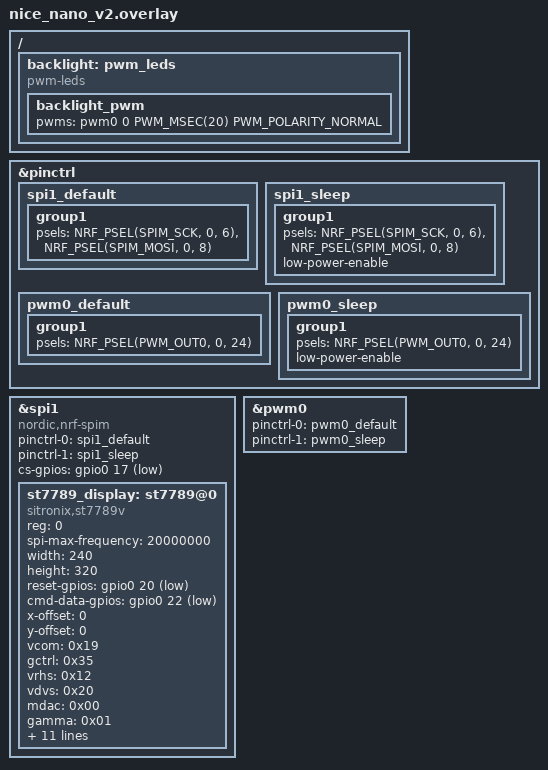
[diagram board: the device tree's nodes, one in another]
// Device tree overlay for ST7789 TFT display connected via SPI
// Add this to your board's .overlay file or include in your keymap


&pinctrl {
    spi1_default: spi1_default {
        group1 {
            psels = <NRF_PSEL(SPIM_SCK, 0, 6)>,   // SCK - Pin 0.06 (D4)
                    <NRF_PSEL(SPIM_MOSI, 0, 8)>;  // MOSI - Pin 0.08 (D6)
        };
    };

    spi1_sleep: spi1_sleep {
        group1 {
            psels = <NRF_PSEL(SPIM_SCK, 0, 6)>,
                    <NRF_PSEL(SPIM_MOSI, 0, 8)>;
            low-power-enable;
        };
    };
};

&spi1 {
    compatible = "nordic,nrf-spim";
    status = "okay";
    pinctrl-0 = <&spi1_default>;
    pinctrl-1 = <&spi1_sleep>;
    pinctrl-names = "default", "sleep";
    cs-gpios = <&gpio0 17 GPIO_ACTIVE_LOW>;  // CS - Pin 0.17 (D10)

    st7789_display: st7789@0 {
        compatible = "sitronix,st7789v";
        reg = <0>;
        spi-max-frequency = <20000000>;  // 20MHz
        
        // Display dimensions
        width = <240>;
        height = <320>;
        
        // Control pins
        reset-gpios = <&gpio0 20 GPIO_ACTIVE_LOW>;  // RST - Pin 0.20 (D2)
        cmd-data-gpios = <&gpio0 22 GPIO_ACTIVE_LOW>; // DC - Pin 0.22 (D3)
        
        // Display configuration
        x-offset = <0>;
        y-offset = <0>;
        vcom = <0x19>;
        gctrl = <0x35>;
        vrhs = <0x12>;
        vdvs = <0x20>;
        mdac = <0x00>;
        gamma = <0x01>;
        colmod = <0x05>;
        lcm = <0x2c>;
        porch-param = [0c 0c 00 33 33];
        cmd2en-param = [5a 69 02 01];
        pwctrl1-param = [a4 a1];
        pvgam-param = [D0 04 0D 11 13 2B 3F 54 4C 18 0D 0B 1F 23];
        nvgam-param = [D0 04 0C 11 13 2C 3F 44 51 2F 1F 1F 20 23];
        ram-param = [00 F0];
        rgb-param = [CD 08 14];
    };
};



// Optional: Configure backlight if your display has one
/ {
    backlight: pwm_leds {
        compatible = "pwm-leds";
        
        backlight_pwm: backlight_pwm {
            pwms = <&pwm0 0 PWM_MSEC(20) PWM_POLARITY_NORMAL>;
        };
    };
};

&pwm0 {
    status = "okay";
    pinctrl-0 = <&pwm0_default>;
    pinctrl-1 = <&pwm0_sleep>;
    pinctrl-names = "default", "sleep";
};

&pinctrl {
    pwm0_default: pwm0_default {
        group1 {
            psels = <NRF_PSEL(PWM_OUT0, 0, 24)>; // BL - Pin 0.24 (D5)
        };
    };

    pwm0_sleep: pwm0_sleep {
        group1 {
            psels = <NRF_PSEL(PWM_OUT0, 0, 24)>;
            low-power-enable;
        };
    };
};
